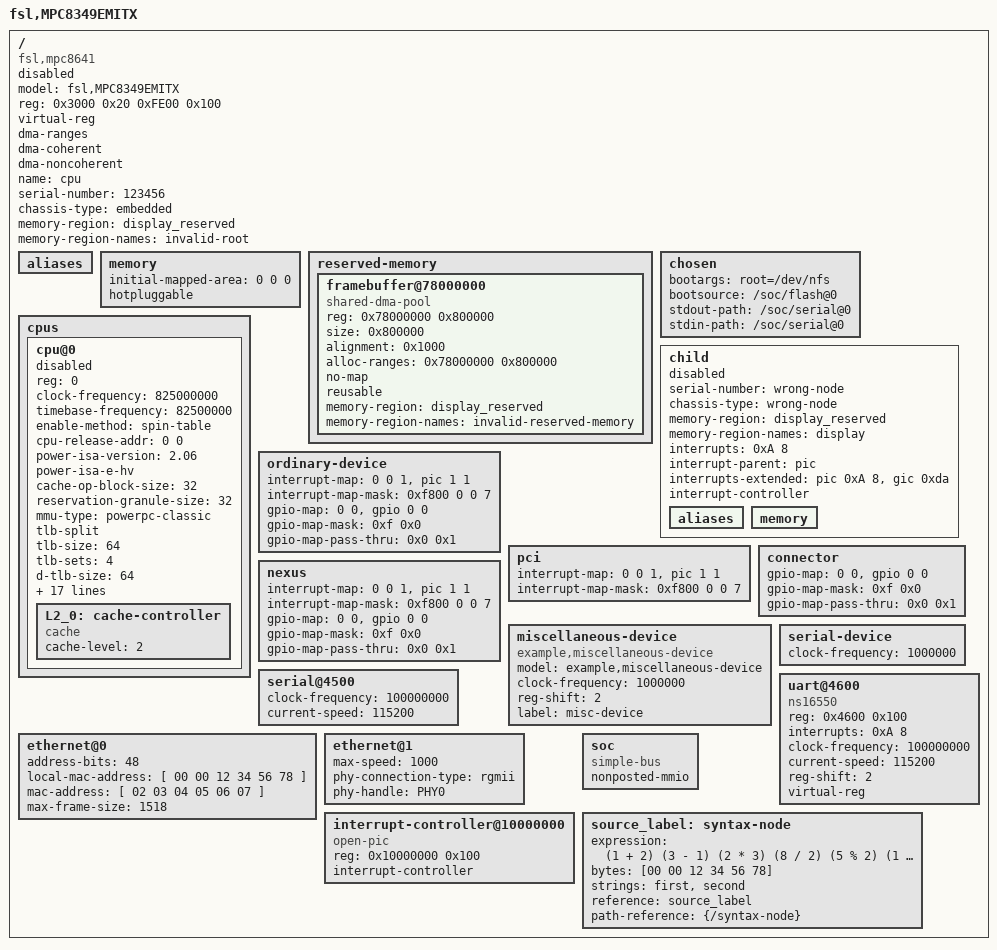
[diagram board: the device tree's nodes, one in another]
/dts-v1/;

/ {
    compatible = "fsl,mpc8641", "ns16550";
    model = "fsl,MPC8349EMITX";
    #address-cells = <1>;
    #size-cells = <1>;

    phandle = <1>;
    status = "disabled";
    reg = <0x3000 0x20 0xFE00 0x100>;
    virtual-reg;
    ranges = <0x0 0xe0000000 0x00100000>;
    dma-ranges;
    dma-coherent;
    dma-noncoherent;
    name = "cpu";
    device_type = "cpu";
    linux,phandle = <1>;
    serial-number = "123456";
    chassis-type = "embedded";
    memory-region = <&display_reserved>; // should not return hover since it is only valid on device nodes
    memory-region-names = "invalid-root"; // should not return hover since it is only valid on device nodes

    aliases {
    };

    memory {
        initial-mapped-area = <0 0 0>;
        hotpluggable;
    };

    reserved-memory {
        #address-cells = <1>;
        #size-cells = <1>;
        ranges;

        framebuffer@78000000 {
            reg = <0x78000000 0x800000>;
            compatible = "shared-dma-pool";
            size = <0x800000>;
            alignment = <0x1000>;
            alloc-ranges = <0x78000000 0x800000>;
            no-map;
            reusable;
            memory-region = <&display_reserved>; // should not return hover since it is only valid outside reserved-memory nodes
            memory-region-names = "invalid-reserved-memory"; // should not return hover since it is only valid outside reserved-memory nodes
        };
    };

    chosen {
        bootargs = "root=/dev/nfs";
        bootsource = "/soc/flash@0";
        stdout-path = "/soc/serial@0";
        stdin-path = "/soc/serial@0";
    };

    cpus {
        #address-cells = <1>;
        #size-cells = <0>;

        cpu@0 {
            device_type = "cpu";
            reg = <0>;
            clock-frequency = <825000000>;
            timebase-frequency = <82500000>;
            status = "disabled";
            enable-method = "spin-table";
            cpu-release-addr = <0 0>;
            power-isa-version = "2.06";
            power-isa-e-hv;
            cache-op-block-size = <32>;
            reservation-granule-size = <32>;
            mmu-type = "powerpc-classic";
            tlb-split;
            tlb-size = <64>;
            tlb-sets = <4>;
            d-tlb-size = <64>;
            d-tlb-sets = <4>;
            i-tlb-size = <64>;
            i-tlb-sets = <4>;
            cache-unified;
            cache-size = <0x8000>;
            cache-sets = <256>;
            cache-block-size = <32>;
            cache-line-size = <32>;
            i-cache-size = <0x8000>;
            i-cache-sets = <256>;
            i-cache-block-size = <32>;
            i-cache-line-size = <32>;
            d-cache-size = <0x8000>;
            d-cache-sets = <256>;
            d-cache-block-size = <32>;
            d-cache-line-size = <32>;
            next-level-cache = <&L2_0>;

            L2_0: cache-controller {
                compatible = "cache";
                cache-level = <2>;
            };
        };
    };

    child {
        serial-number = "wrong-node"; // should not return hover since it is only a root property
        chassis-type = "wrong-node"; // should not return hover since it is only a root property

        memory-region = <&display_reserved>;
        memory-region-names = "display";
        status = "okay";
        status = "disabled";
        status = "reserved";
        status = "fail";
        status = "fail-sss";
        interrupts = <0xA 8>;
        interrupt-parent = <&pic>;
        interrupts-extended = <&pic 0xA 8>, <&gic 0xda>;
        interrupt-controller;
        #interrupt-cells = <2>;

        aliases { // should not return hover since it is only a root node
        };

        memory { // should not return hover since it is only a root node
        };
    };

    ordinary-device {
        interrupt-map = <0 0 1 &pic 1 1>; // should not return hover since it is only valid on nexus nodes
        interrupt-map-mask = <0xf800 0 0 7>; // should not return hover since it is only valid on nexus nodes
        gpio-map = <0 0 &gpio 0 0>; // should not return hover since it is only valid on nexus nodes
        gpio-map-mask = <0xf 0x0>; // should not return hover since it is only valid on nexus nodes
        gpio-map-pass-thru = <0x0 0x1>; // should not return hover since it is only valid on nexus nodes
    };

    pci {
        #interrupt-cells = <1>;
        interrupt-map = <0 0 1 &pic 1 1>;
        interrupt-map-mask = <0xf800 0 0 7>;
    };

    connector {
        #gpio-cells = <2>;
        gpio-map = <0 0 &gpio 0 0>;
        gpio-map-mask = <0xf 0x0>;
        gpio-map-pass-thru = <0x0 0x1>;
    };

    nexus {
        interrupt-map = <0 0 1 &pic 1 1>; // should not return hover since the node name alone does not make this a nexus
        interrupt-map-mask = <0xf800 0 0 7>; // should not return hover since the node name alone does not make this a nexus
        gpio-map = <0 0 &gpio 0 0>; // should not return hover since the node name alone does not make this a nexus
        gpio-map-mask = <0xf 0x0>; // should not return hover since the node name alone does not make this a nexus
        gpio-map-pass-thru = <0x0 0x1>; // should not return hover since the node name alone does not make this a nexus
    };

    miscellaneous-device {
        compatible = "example,miscellaneous-device";
        model = "example,miscellaneous-device";
        #address-cells = <1>;
        #size-cells = <1>;
        clock-frequency = <1000000>;
        reg-shift = <2>;
        label = "misc-device";
    };

    serial-device {
        clock-frequency = <1000000>;
    };

    serial@4500 {
        clock-frequency = <100000000>;
        current-speed = <115200>;
    };

    uart@4600 {
        compatible = "ns16550";
        reg = <0x4600 0x100>;
        interrupts = <0xA 8>;
        clock-frequency = <100000000>;
        current-speed = <115200>;
        reg-shift = <2>;
        virtual-reg;
    };

    ethernet@0 {
        address-bits = <48>;
        local-mac-address = [ 00 00 12 34 56 78 ];
        mac-address = [ 02 03 04 05 06 07 ];
        max-frame-size = <1518>;
    };

    ethernet@1 {
        max-speed = <1000>;
        phy-connection-type = "rgmii";
        phy-handle = <&PHY0>;
    };

    interrupt-controller@10000000 {
        compatible = "open-pic";
        reg = <0x10000000 0x100>;
        interrupt-controller;
        #interrupt-cells = <2>;
        #address-cells = <0>;
    };

    soc {
        compatible = "simple-bus";
        ranges;
        nonposted-mmio;
    };
};

/include/ "included.dtsi"

/memreserve/ 0x10000000 0x4000;

/ {
    source_label: syntax-node {
        expression = <(1 + 2) (3 - 1) (2 * 3) (8 / 2) (5 % 2) (1 & 3) (1 | 2) (1 ^ 2) (~1) (4 << 1) (4 >> 1) (1 && 0) (1 || 0) (!0) (1 < 2) (2 > 1) (1 <= 2) (3 >= 2) (1 == 1) (1 != 2) (1 ? 2 : 3)>;
        bytes = [00 00 12 34 56 78];
        strings = "first", "second";
        reference = <&source_label>;
        path-reference = <&{/syntax-node}>;
    };

    /delete-node/ obsolete-node;
    /delete-property/ obsolete-property;
};
